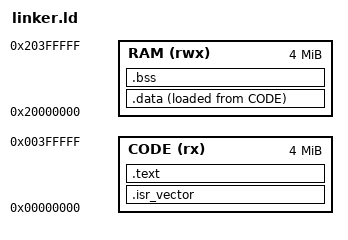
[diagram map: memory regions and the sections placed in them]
ENTRY(Reset_Handler)

MEMORY
{
    CODE (rx)  : ORIGIN = 0x00000000, LENGTH = 4M
    RAM  (rwx) : ORIGIN = 0x20000000, LENGTH = 4M
}

__stack_top = ORIGIN(RAM) + LENGTH(RAM);

SECTIONS
{
    .isr_vector :
    {
        KEEP(*(.isr_vector))
    } > CODE

    .text :
    {
        *(.text*)
        *(.rodata*)
        *(.ARM.exidx*)
        . = ALIGN(4);
    } > CODE

    .data :
    {
        . = ALIGN(4);
        __data_start__ = .;
        *(.data*)
        . = ALIGN(4);
        __data_end__ = .;
    } > RAM AT > CODE

    __data_load__ = LOADADDR(.data);

    .bss (NOLOAD) :
    {
        . = ALIGN(4);
        __bss_start__ = .;
        *(.bss*)
        *(COMMON)
        . = ALIGN(4);
        __bss_end__ = .;
    } > RAM
}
